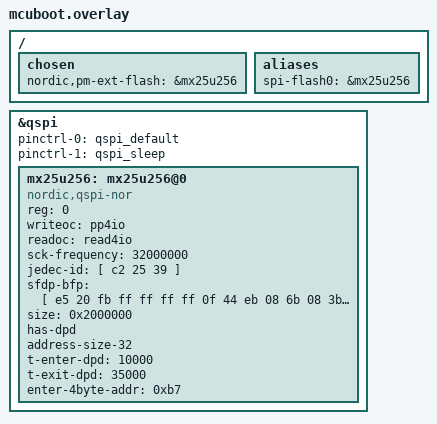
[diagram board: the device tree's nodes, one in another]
/ {
	chosen {
		// nordic,pm-ext-flash = &mx25r64;
		nordic,pm-ext-flash = &mx25u256;
	};
	aliases {
		spi-flash0 = &mx25u256;
	};
};

/delete-node/ &mx25r64;
&qspi {
	status = "okay";
	pinctrl-0 = <&qspi_default>;
	pinctrl-1 = <&qspi_sleep>;
	pinctrl-names = "default", "sleep";
	mx25u256: mx25u256@0 {
		compatible = "nordic,qspi-nor";
		reg = <0>;
		/* MX25U256 supports only pp and pp4io */
		writeoc = "pp4io";
		/* MX25U256 supports all readoc options */
		readoc = "read4io";
		sck-frequency = <32000000>;//最高 48Mhz
		jedec-id = [ c2 25 39 ];
		sfdp-bfp = [ 
			e5 20 fb ff  ff ff ff 0f  44 eb 08 6b  08 3b 04 bb 
			fe ff ff ff  ff ff 00 ff  ff ff 44 eb  0c 20 0f 52 
			10 d8 00 ff  25 52 dd 00  84 a5 04 e2  44 03 17 38 
			30 b0 30 b0  f7 bd d5 5c  4a 9e 29 ff  f0 50 f9 85
		];
		size = <0x2000000>;// 32M
		has-dpd;
		address-size-32;
		t-enter-dpd = <10000>;
		t-exit-dpd = <35000>;
		enter-4byte-addr = <0xb7>;
	};
};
